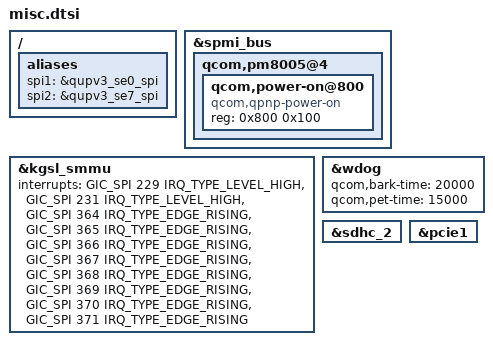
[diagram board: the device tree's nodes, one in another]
/*
 * Copyright (c) 2024, MeizuCustoms enthusiasts
 *
 * This program is free software; you can redistribute it and/or modify
 * it under the terms of the GNU General Public License version 2 and
 * only version 2 as published by the Free Software Foundation.
 *
 * This program is distributed in the hope that it will be useful,
 * but WITHOUT ANY WARRANTY; without even the implied warranty of
 * MERCHANTABILITY or FITNESS FOR A PARTICULAR PURPOSE.  See the
 * GNU General Public License for more details.
 */

/ {
    aliases {
        spi1 = &qupv3_se0_spi;
		spi2 = &qupv3_se7_spi;
    };
};

&spmi_bus {
	qcom,pm8005@4 {
        qcom,power-on@800 {
            compatible = "qcom,qpnp-power-on";
            reg = <0x800 0x100>;
        };
    };
};

&kgsl_smmu {
    interrupts = <GIC_SPI 229 IRQ_TYPE_LEVEL_HIGH>, 
				<GIC_SPI 231 IRQ_TYPE_LEVEL_HIGH>, 
				<GIC_SPI 364 IRQ_TYPE_EDGE_RISING>, 
				<GIC_SPI 365 IRQ_TYPE_EDGE_RISING>, 
				<GIC_SPI 366 IRQ_TYPE_EDGE_RISING>, 
				<GIC_SPI 367 IRQ_TYPE_EDGE_RISING>, 
				<GIC_SPI 368 IRQ_TYPE_EDGE_RISING>, 
				<GIC_SPI 369 IRQ_TYPE_EDGE_RISING>, 
				<GIC_SPI 370 IRQ_TYPE_EDGE_RISING>, 
				<GIC_SPI 371 IRQ_TYPE_EDGE_RISING>;
};

&wdog {
    qcom,bark-time = <20000>;
    qcom,pet-time = <15000>;
};

&sdhc_2 {
	/delete-property/ cd-gpios;
};

&pcie1 {
    /delete-property/ perst-gpio;
};

